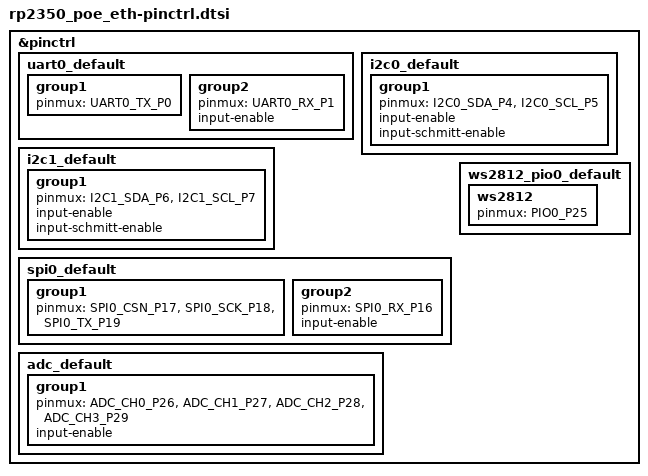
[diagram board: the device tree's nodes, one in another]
/*
 * Copyright (c) 2026 Richard Osterloh
 *
 * SPDX-License-Identifier: Apache-2.0
 */

#include <zephyr/dt-bindings/pinctrl/rpi-pico-rp2350a-pinctrl.h>

&pinctrl {
	uart0_default: uart0_default {
		group1 {
			pinmux = <UART0_TX_P0>;
		};

		group2 {
			pinmux = <UART0_RX_P1>;
			input-enable;
		};
	};

	i2c0_default: i2c0_default {
		group1 {
			pinmux = <I2C0_SDA_P4>, <I2C0_SCL_P5>;
			input-enable;
			input-schmitt-enable;
		};
	};

	i2c1_default: i2c1_default {
		group1 {
			pinmux = <I2C1_SDA_P6>, <I2C1_SCL_P7>;
			input-enable;
			input-schmitt-enable;
		};
	};

	/*
	 * SPI0 is dedicated to the onboard W6300. Unlike the WIZnet
	 * W6300-EVB-Pico2 (which bit-bangs the bus), the Waveshare pin
	 * assignment lands on the RP2350 SPI0 hardware function, so the
	 * peripheral is used directly.
	 */
	spi0_default: spi0_default {
		group1 {
			pinmux = <SPI0_CSN_P17>, <SPI0_SCK_P18>, <SPI0_TX_P19>;
		};

		group2 {
			pinmux = <SPI0_RX_P16>;
			input-enable;
		};
	};

	/* Onboard WS2812 status LED on GP25, driven by PIO0. */
	ws2812_pio0_default: ws2812_pio0_default {
		ws2812 {
			pinmux = <PIO0_P25>;
		};
	};

	adc_default: adc_default {
		group1 {
			pinmux = <ADC_CH0_P26>, <ADC_CH1_P27>, <ADC_CH2_P28>, <ADC_CH3_P29>;
			input-enable;
		};
	};
};
